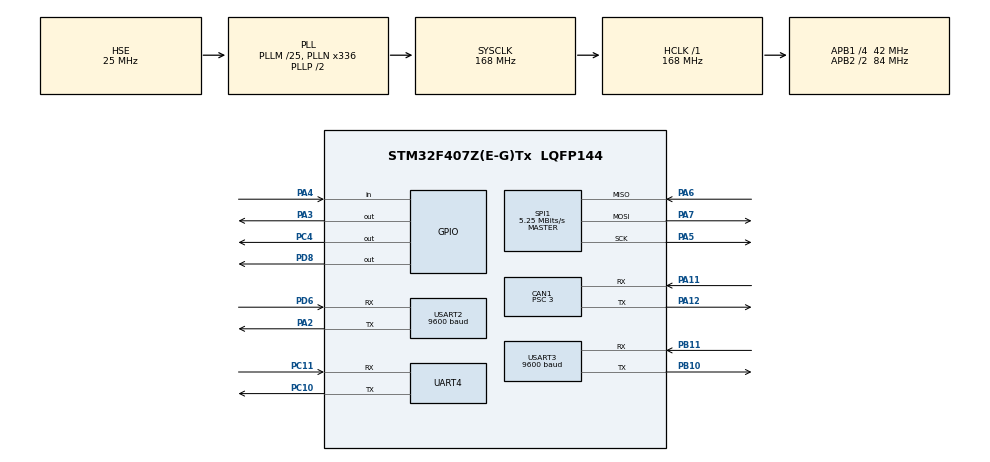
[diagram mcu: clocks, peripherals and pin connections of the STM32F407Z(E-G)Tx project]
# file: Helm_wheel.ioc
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CAN1.BS1=CAN_BS1_7TQ
CAN1.BS2=CAN_BS2_6TQ
CAN1.CalculateBaudRate=1000000
CAN1.CalculateTimeBit=1000
CAN1.CalculateTimeQuantum=71.42857142857143
CAN1.Prescaler=3
Dma.Request0=UART4_RX
Dma.Request1=UART4_TX
Dma.Request2=USART2_TX
Dma.Request3=USART2_RX
Dma.Request4=USART3_TX
Dma.Request5=USART3_RX
Dma.UART4_RX.0.Direction=DMA_PERIPH_TO_MEMORY
Dma.UART4_RX.0.FIFOMode=DMA_FIFOMODE_DISABLE
Dma.UART4_RX.0.Instance=DMA1_Stream2
Dma.UART4_RX.0.MemDataAlignment=DMA_MDATAALIGN_BYTE
Dma.UART4_RX.0.MemInc=DMA_MINC_ENABLE
Dma.UART4_RX.0.Mode=DMA_CIRCULAR
Dma.UART4_RX.0.PeriphDataAlignment=DMA_PDATAALIGN_BYTE
Dma.UART4_RX.0.PeriphInc=DMA_PINC_DISABLE
Dma.UART4_RX.0.Priority=DMA_PRIORITY_LOW
Dma.UART4_TX.1.Direction=DMA_MEMORY_TO_PERIPH
Dma.UART4_TX.1.FIFOMode=DMA_FIFOMODE_DISABLE
Dma.UART4_TX.1.Instance=DMA1_Stream4
Dma.UART4_TX.1.MemDataAlignment=DMA_MDATAALIGN_BYTE
Dma.UART4_TX.1.MemInc=DMA_MINC_ENABLE
Dma.UART4_TX.1.Mode=DMA_CIRCULAR
Dma.UART4_TX.1.PeriphDataAlignment=DMA_PDATAALIGN_BYTE
Dma.UART4_TX.1.PeriphInc=DMA_PINC_DISABLE
Dma.UART4_TX.1.Priority=DMA_PRIORITY_LOW
Dma.USART2_RX.3.Direction=DMA_PERIPH_TO_MEMORY
Dma.USART2_RX.3.FIFOMode=DMA_FIFOMODE_DISABLE
Dma.USART2_RX.3.Instance=DMA1_Stream5
Dma.USART2_RX.3.MemDataAlignment=DMA_MDATAALIGN_BYTE
Dma.USART2_RX.3.MemInc=DMA_MINC_ENABLE
Dma.USART2_RX.3.Mode=DMA_CIRCULAR
Dma.USART2_RX.3.PeriphDataAlignment=DMA_PDATAALIGN_BYTE
Dma.USART2_RX.3.PeriphInc=DMA_PINC_DISABLE
Dma.USART2_RX.3.Priority=DMA_PRIORITY_LOW
Dma.USART2_TX.2.Direction=DMA_MEMORY_TO_PERIPH
Dma.USART2_TX.2.FIFOMode=DMA_FIFOMODE_DISABLE
Dma.USART2_TX.2.Instance=DMA1_Stream6
Dma.USART2_TX.2.MemDataAlignment=DMA_MDATAALIGN_BYTE
Dma.USART2_TX.2.MemInc=DMA_MINC_ENABLE
Dma.USART2_TX.2.Mode=DMA_CIRCULAR
Dma.USART2_TX.2.PeriphDataAlignment=DMA_PDATAALIGN_BYTE
Dma.USART2_TX.2.PeriphInc=DMA_PINC_DISABLE
Dma.USART2_TX.2.Priority=DMA_PRIORITY_LOW
Dma.USART3_RX.5.Direction=DMA_PERIPH_TO_MEMORY
Dma.USART3_RX.5.FIFOMode=DMA_FIFOMODE_DISABLE
Dma.USART3_RX.5.Instance=DMA1_Stream1
Dma.USART3_RX.5.MemDataAlignment=DMA_MDATAALIGN_BYTE
Dma.USART3_RX.5.MemInc=DMA_MINC_ENABLE
Dma.USART3_RX.5.Mode=DMA_CIRCULAR
Dma.USART3_RX.5.PeriphDataAlignment=DMA_PDATAALIGN_BYTE
Dma.USART3_RX.5.PeriphInc=DMA_PINC_DISABLE
Dma.USART3_RX.5.Priority=DMA_PRIORITY_LOW
Dma.USART3_TX.4.Direction=DMA_MEMORY_TO_PERIPH
Dma.USART3_TX.4.FIFOMode=DMA_FIFOMODE_DISABLE
Dma.USART3_TX.4.Instance=DMA1_Stream3
Dma.USART3_TX.4.MemDataAlignment=DMA_MDATAALIGN_BYTE
Dma.USART3_TX.4.MemInc=DMA_MINC_ENABLE
Dma.USART3_TX.4.Mode=DMA_CIRCULAR
Dma.USART3_TX.4.PeriphDataAlignment=DMA_PDATAALIGN_BYTE
Dma.USART3_TX.4.PeriphInc=DMA_PINC_DISABLE
Dma.USART3_TX.4.Priority=DMA_PRIORITY_LOW
FREERTOS.Tasks01=defaultTask,0,128,StartDefaultTask,Default,NULL,Dynamic,NULL,NULL;Task_remote,0,128,task_intitask_remote,Default,NULL,Dynamic,NULL,NULL;Task_tx_to_uppe,0,128,tx_to_upper,Default,NULL,Dynamic,NULL,NULL
Mcu.Family=STM32F4
Mcu.Name=STM32F407Z(E-G)Tx
Mcu.Package=LQFP144
NVIC.CAN1_RX0_IRQn=true\:5\:0\:false\:false\:true\:true\:true\:true\:true
NVIC.DMA1_Stream1_IRQn=true\:5\:0\:false\:false\:true\:true\:false\:true\:true
NVIC.DMA1_Stream2_IRQn=true\:5\:0\:false\:false\:true\:true\:false\:true\:true
NVIC.DMA1_Stream3_IRQn=true\:5\:0\:false\:false\:true\:true\:false\:true\:true
NVIC.DMA1_Stream4_IRQn=true\:5\:0\:false\:false\:true\:true\:false\:true\:true
NVIC.DMA1_Stream5_IRQn=true\:5\:0\:false\:false\:true\:true\:false\:true\:true
NVIC.DMA1_Stream6_IRQn=true\:5\:0\:false\:false\:true\:true\:false\:true\:true
NVIC.PriorityGroup=NVIC_PRIORITYGROUP_4
NVIC.TIM7_IRQn=true\:5\:0\:false\:false\:true\:true\:true\:true\:true
NVIC.UART4_IRQn=true\:5\:0\:false\:false\:true\:true\:true\:true\:true
NVIC.USART2_IRQn=true\:5\:0\:false\:false\:true\:true\:true\:true\:true
NVIC.USART3_IRQn=true\:5\:0\:false\:false\:true\:true\:true\:true\:true
PA11.Mode=CAN_Activate
PA11.Signal=CAN1_RX
PA12.Mode=CAN_Activate
PA12.Signal=CAN1_TX
PA13.Mode=Serial_Wire
PA13.Signal=SYS_JTMS-SWDIO
PA14.Mode=Serial_Wire
PA14.Signal=SYS_JTCK-SWCLK
PA2.Mode=Asynchronous
PA2.Signal=USART2_TX
PA3.Signal=GPIO_Output
PA4.Signal=GPIO_Input
PA5.Mode=Full_Duplex_Master
PA5.Signal=SPI1_SCK
PA6.Mode=Full_Duplex_Master
PA6.Signal=SPI1_MISO
PA7.Mode=Full_Duplex_Master
PA7.Signal=SPI1_MOSI
PB10.Mode=Asynchronous
PB10.Signal=USART3_TX
PB11.Mode=Asynchronous
PB11.Signal=USART3_RX
PC10.Mode=Asynchronous
PC10.Signal=UART4_TX
PC11.Mode=Asynchronous
PC11.Signal=UART4_RX
PC4.Signal=GPIO_Output
PD6.Mode=Asynchronous
PD6.Signal=USART2_RX
PD8.Signal=GPIO_Output
PH0-OSC_IN.Mode=HSE-External-Oscillator
PH0-OSC_IN.Signal=RCC_OSC_IN
PH1-OSC_OUT.Mode=HSE-External-Oscillator
PH1-OSC_OUT.Signal=RCC_OSC_OUT
ProjectManager.HeapSize=0x200
ProjectManager.StackSize=0x400
ProjectManager.TargetToolchain=MDK-ARM V5.32
RCC.48MHZClocksFreq_Value=84000000
RCC.AHBFreq_Value=168000000
RCC.APB1CLKDivider=RCC_HCLK_DIV4
RCC.APB1Freq_Value=42000000
RCC.APB1TimFreq_Value=84000000
RCC.APB2CLKDivider=RCC_HCLK_DIV2
RCC.APB2Freq_Value=84000000
RCC.APB2TimFreq_Value=168000000
RCC.CortexFreq_Value=168000000
RCC.HCLKFreq_Value=168000000
RCC.HSE_VALUE=25000000
RCC.HSI_VALUE=16000000
RCC.LSE_VALUE=32768
RCC.PLLM=25
RCC.PLLN=336
RCC.PLLSourceVirtual=RCC_PLLSOURCE_HSE
RCC.SYSCLKFreq_VALUE=168000000
RCC.SYSCLKSource=RCC_SYSCLKSOURCE_PLLCLK
RCC.VCOOutputFreq_Value=336000000
SPI1.BaudRatePrescaler=SPI_BAUDRATEPRESCALER_16
SPI1.CalculateBaudRate=5.25 MBits/s
SPI1.Direction=SPI_DIRECTION_2LINES
SPI1.Mode=SPI_MODE_MASTER
SPI1.VirtualType=VM_MASTER
TIM7.Period=200-1
TIM7.Prescaler=8400-1
UART4.VirtualMode=Asynchronous
USART2.BaudRate=9600
USART2.VirtualMode=VM_ASYNC
USART3.BaudRate=9600
USART3.VirtualMode=VM_ASYNC
VP_FREERTOS_VS_CMSIS_V1.Mode=CMSIS_V1
VP_TIM7_VS_ClockSourceINT.Mode=Enable_Timer
board=custom

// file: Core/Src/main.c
/* USER CODE BEGIN Header */
/**
  ******************************************************************************
  * @file           : main.c
  * @brief          : Main program body
  ******************************************************************************
  * @attention
  *
  * Copyright (c) 2024 STMicroelectronics.
  * All rights reserved.
  *
  * This software is licensed under terms that can be found in the LICENSE file
  * in the root directory of this software component.
  * If no LICENSE file comes with this software, it is provided AS-IS.
  *
  ******************************************************************************
  */
/* USER CODE END Header */
#include "main.h"
#include "cmsis_os.h"
#include "can.h"
#include "dma.h"
#include "spi.h"
#include "tim.h"
#include "usart.h"
#include "gpio.h"

/* USER CODE BEGIN Includes */
#include "startup_main.h"
/* USER CODE END Includes */

void SystemClock_Config(void);
void MX_FREERTOS_Init(void);

int main(void)
{

  /* MCU Configuration--------------------------------------------------------*/

  /* Reset of all peripherals, Initializes the Flash interface and the Systick. */
  HAL_Init();

  /* Configure the system clock */
  SystemClock_Config();

  /* Initialize all configured peripherals */
  MX_GPIO_Init();
  MX_DMA_Init();
  MX_CAN1_Init();
  MX_SPI1_Init();
  MX_TIM7_Init();
  MX_UART4_Init();
  MX_USART2_UART_Init();
  MX_USART3_UART_Init();
  /* USER CODE BEGIN 2 */

  startup_main();
  /* USER CODE END 2 */

  /* Call init function for freertos objects (in cmsis_os2.c) */
  MX_FREERTOS_Init();

  /* Start scheduler */
  osKernelStart();

  /* We should never get here as control is now taken by the scheduler */

  /* Infinite loop */
  while (1)
  {

  }
}

void SystemClock_Config(void)
{
  RCC_OscInitTypeDef RCC_OscInitStruct = {0};
  RCC_ClkInitTypeDef RCC_ClkInitStruct = {0};

  /** Configure the main internal regulator output voltage
  */
  __HAL_RCC_PWR_CLK_ENABLE();
  __HAL_PWR_VOLTAGESCALING_CONFIG(PWR_REGULATOR_VOLTAGE_SCALE1);

  /** Initializes the RCC Oscillators according to the specified parameters
  * in the RCC_OscInitTypeDef structure.
  */
  RCC_OscInitStruct.OscillatorType = RCC_OSCILLATORTYPE_HSE;
  RCC_OscInitStruct.HSEState = RCC_HSE_ON;
  RCC_OscInitStruct.PLL.PLLState = RCC_PLL_ON;
  RCC_OscInitStruct.PLL.PLLSource = RCC_PLLSOURCE_HSE;
  RCC_OscInitStruct.PLL.PLLM = 25;
  RCC_OscInitStruct.PLL.PLLN = 336;
  RCC_OscInitStruct.PLL.PLLP = RCC_PLLP_DIV2;
  RCC_OscInitStruct.PLL.PLLQ = 4;
  if (HAL_RCC_OscConfig(&RCC_OscInitStruct) != HAL_OK)
  {
    Error_Handler();
  }

  /** Initializes the CPU, AHB and APB buses clocks
  */
  RCC_ClkInitStruct.ClockType = RCC_CLOCKTYPE_HCLK|RCC_CLOCKTYPE_SYSCLK
                              |RCC_CLOCKTYPE_PCLK1|RCC_CLOCKTYPE_PCLK2;
  RCC_ClkInitStruct.SYSCLKSource = RCC_SYSCLKSOURCE_PLLCLK;
  RCC_ClkInitStruct.AHBCLKDivider = RCC_SYSCLK_DIV1;
  RCC_ClkInitStruct.APB1CLKDivider = RCC_HCLK_DIV4;
  RCC_ClkInitStruct.APB2CLKDivider = RCC_HCLK_DIV2;

  if (HAL_RCC_ClockConfig(&RCC_ClkInitStruct, FLASH_LATENCY_5) != HAL_OK)
  {
    Error_Handler();
  }
}

void Error_Handler(void)
{
  __disable_irq();
  while (1)
  {
  }
}

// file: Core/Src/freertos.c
/* USER CODE BEGIN Header */
/**
  ******************************************************************************
  * File Name          : freertos.c
  * Description        : Code for freertos applications
  ******************************************************************************
  * @attention
  *
  * Copyright (c) 2024 STMicroelectronics.
  * All rights reserved.
  *
  * This software is licensed under terms that can be found in the LICENSE file
  * in the root directory of this software component.
  * If no LICENSE file comes with this software, it is provided AS-IS.
  *
  ******************************************************************************
  */
/* USER CODE END Header */

#include "FreeRTOS.h"
#include "task.h"
#include "main.h"
#include "cmsis_os.h"

/* USER CODE BEGIN Variables */
extern uint8_t odometer_data[12];
/* USER CODE END Variables */
osThreadId defaultTaskHandle;
osThreadId Task_remoteHandle;
osThreadId Task_tx_to_uppeHandle;

void StartDefaultTask(void const * argument);
void task_intitask_remote(void const * argument);
void tx_to_upper(void const * argument);

void MX_FREERTOS_Init(void); /* (MISRA C 2004 rule 8.1) */

/* GetIdleTaskMemory prototype (linked to static allocation support) */
void vApplicationGetIdleTaskMemory( StaticTask_t **ppxIdleTaskTCBBuffer, StackType_t **ppxIdleTaskStackBuffer, uint32_t *pulIdleTaskStackSize );

/* USER CODE BEGIN GET_IDLE_TASK_MEMORY */
static StaticTask_t xIdleTaskTCBBuffer;
static StackType_t xIdleStack[configMINIMAL_STACK_SIZE];

void vApplicationGetIdleTaskMemory( StaticTask_t **ppxIdleTaskTCBBuffer, StackType_t **ppxIdleTaskStackBuffer, uint32_t *pulIdleTaskStackSize )
{
  *ppxIdleTaskTCBBuffer = &xIdleTaskTCBBuffer;
  *ppxIdleTaskStackBuffer = &xIdleStack[0];
  *pulIdleTaskStackSize = configMINIMAL_STACK_SIZE;
  /* place for user code */
}
/* USER CODE END GET_IDLE_TASK_MEMORY */

void MX_FREERTOS_Init(void) {

  /* Create the thread(s) */
  /* definition and creation of defaultTask */
  osThreadDef(defaultTask, StartDefaultTask, osPriorityNormal, 0, 128);
  defaultTaskHandle = osThreadCreate(osThread(defaultTask), NULL);

  /* definition and creation of Task_remote */
  osThreadDef(Task_remote, task_intitask_remote, osPriorityNormal, 0, 128);
  Task_remoteHandle = osThreadCreate(osThread(Task_remote), NULL);

  /* definition and creation of Task_tx_to_uppe */
  osThreadDef(Task_tx_to_uppe, tx_to_upper, osPriorityNormal, 0, 128);
  Task_tx_to_uppeHandle = osThreadCreate(osThread(Task_tx_to_uppe), NULL);

}

void StartDefaultTask(void const * argument)
{
  for(;;)
  {
    osDelay(1);
  }
}

void task_intitask_remote(void const * argument)
{
  for(;;)
  {
    osDelay(1);
  }
}

__weak void tx_to_upper(void const * argument)
{
  for(;;)
  {
    osDelay(1);
  }
}
